VERSION ""

NS_ :

BS_:

BU_: TCU Gateway BCM PCM BECM

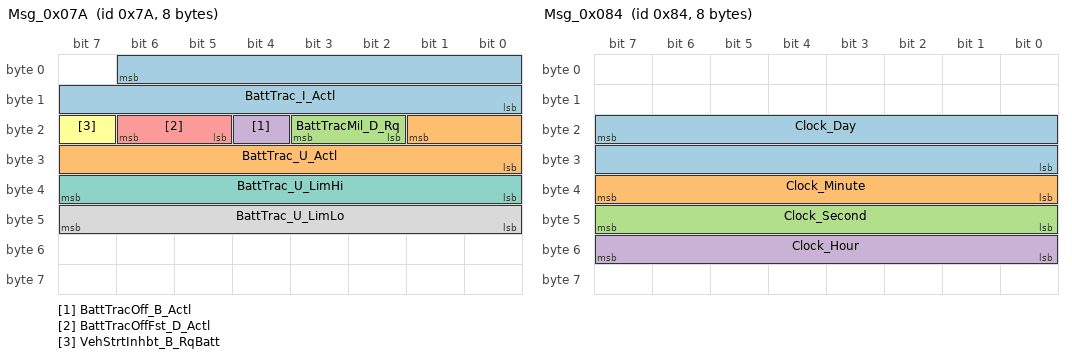
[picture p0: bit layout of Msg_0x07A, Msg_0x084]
BO_ 122 Msg_0x07A: 8 Gateway
 SG_ BattTrac_I_Actl : 6|15@0+ (0.05,-750) [-750|888.25] "A" Vector__XXX
 SG_ BattTrac_U_Actl : 17|10@0+ (0.5,0) [0|510.5] "V" Vector__XXX
 SG_ BattTracMil_D_Rq : 19|2@0+ (1,0) [0|3] "" Vector__XXX
 SG_ BattTracOff_B_Actl : 20|1@0+ (1,0) [0|1] "" Vector__XXX
 SG_ BattTracOffFst_D_Actl : 22|2@0+ (1,0) [0|3] "" Vector__XXX
 SG_ VehStrtInhbt_B_RqBatt : 23|1@0+ (1,0) [0|1] "" Vector__XXX
 SG_ BattTrac_U_LimHi : 39|8@0+ (2,0) [0|510] "V" Vector__XXX
 SG_ BattTrac_U_LimLo : 47|8@0+ (2,0) [0|510] "V" Vector__XXX

BO_ 132 Msg_0x084: 8 Gateway
 SG_ Clock_Day : 23|16@0+ (1,0) [0|65535] "" Vector__XXX
 SG_ Clock_Minute : 39|8@0+ (1,0) [0|59] "min" Vector__XXX
 SG_ Clock_Second : 47|8@0+ (1,0) [0|59] "s" Vector__XXX
 SG_ Clock_Hour : 55|8@0+ (1,0) [0|23] "h" Vector__XXX

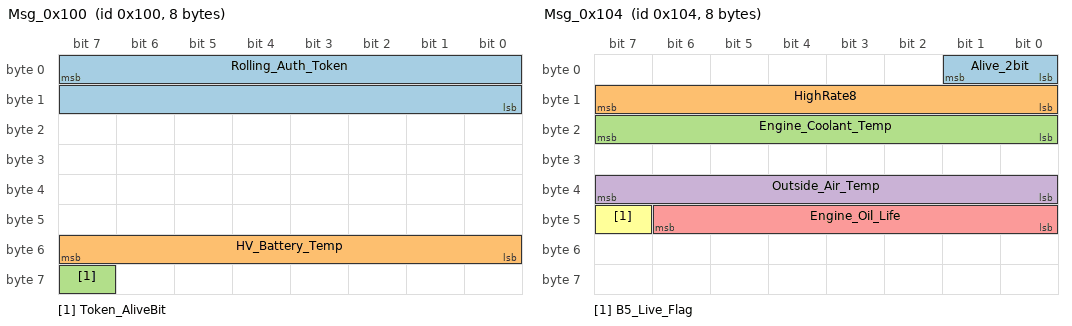
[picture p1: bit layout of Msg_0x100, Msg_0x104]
BO_ 256 Msg_0x100: 8 BCM
 SG_ Rolling_Auth_Token : 7|16@0+ (1,0) [0|65535] "" Vector__XXX
 SG_ HV_Battery_Temp : 55|8@0+ (0.5,-50) [-40|80] "degC" Vector__XXX
 SG_ Token_AliveBit : 63|1@0+ (1,0) [0|1] "" Vector__XXX

BO_ 257 Msg_0x101: 8 Gateway
 SG_ Brake_Pressed : 32|1@0+ (1,0) [0|1] "" Vector__XXX
 SG_ Gear_Selector : 29|2@0+ (1,0) [0|3] "" Vector__XXX

BO_ 259 Msg_0x103: 8 Gateway
 SG_ Accelerator_Demand : 7|16@0+ (0.1887,-24188) [0|100] "%" Vector__XXX
 SG_ Engine_RPM_Raw : 23|16@0+ (2,-114688) [0|8000] "rpm" Vector__XXX

BO_ 260 Msg_0x104: 8 Gateway
 SG_ Alive_2bit : 1|2@0+ (1,0) [0|3] "" Vector__XXX
 SG_ HighRate8 : 15|8@0+ (1,0) [0|255] "" Vector__XXX
 SG_ Engine_Coolant_Temp : 23|8@0+ (1.0,-60) [-40|140] "degC" Vector__XXX
 SG_ Outside_Air_Temp : 39|8@0+ (0.25,0) [0|63.5] "degC" Vector__XXX
 SG_ Engine_Oil_Life : 46|7@0+ (1,0) [0|100] "%" Vector__XXX
 SG_ B5_Live_Flag : 47|1@0+ (1,0) [0|1] "" Vector__XXX

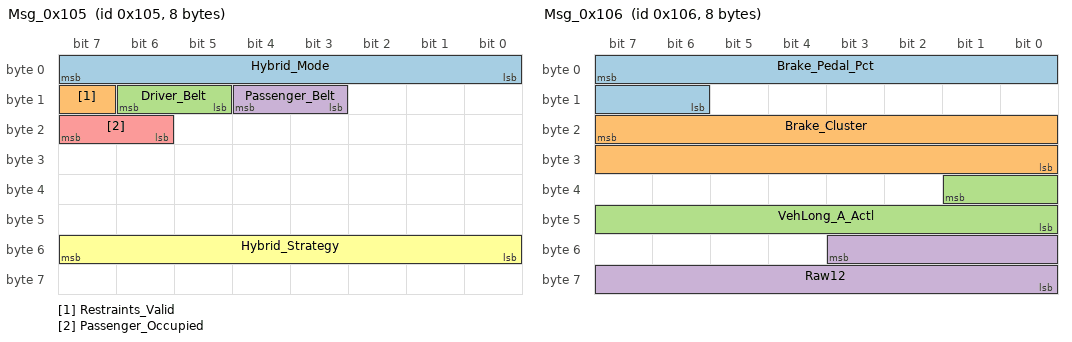
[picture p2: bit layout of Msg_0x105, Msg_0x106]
BO_ 261 Msg_0x105: 8 Gateway
 SG_ Hybrid_Mode : 7|8@0+ (1,0) [0|255] "" Vector__XXX
 SG_ Restraints_Valid : 15|1@0+ (1,0) [0|1] "" Vector__XXX
 SG_ Driver_Belt : 14|2@0+ (1,0) [0|3] "" Vector__XXX
 SG_ Passenger_Belt : 12|2@0+ (1,0) [0|3] "" Vector__XXX
 SG_ Passenger_Occupied : 23|2@0+ (1,0) [0|3] "" Vector__XXX
 SG_ Hybrid_Strategy : 55|8@0+ (1,0) [0|255] "" Vector__XXX

BO_ 262 Msg_0x106: 8 Gateway
 SG_ Brake_Pedal_Pct : 7|10@0+ (0.09775,0) [0|100] "%" Vector__XXX
 SG_ Brake_Cluster : 23|16@0+ (1,0) [0|65535] "" Vector__XXX
 SG_ VehLong_A_Actl : 33|10@0+ (0.035,-17.9) [-17.9|17.85] "m/s2" Vector__XXX
 SG_ Raw12 : 51|12@0+ (1,0) [0|4095] "" Vector__XXX

BO_ 263 Msg_0x107: 8 Gateway
 SG_ Vehicle_Speed : 7|16@0+ (0.01,0) [0|260] "km/h" Vector__XXX
 SG_ Park_Latch : 23|8@0+ (1,0) [0|255] "" Vector__XXX

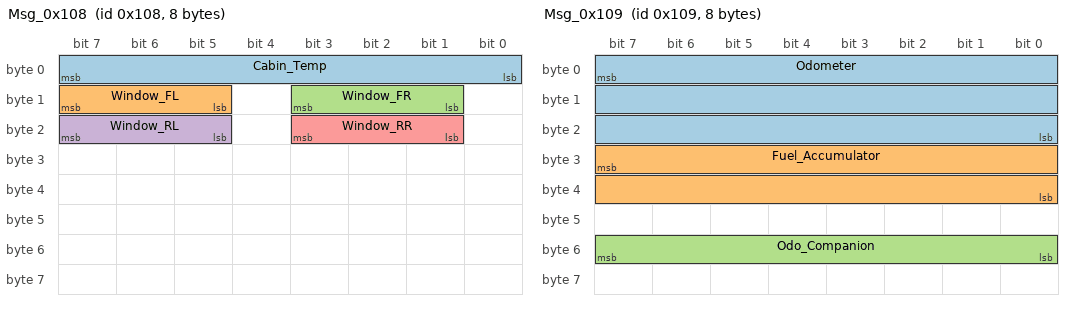
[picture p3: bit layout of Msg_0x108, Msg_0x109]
BO_ 264 Msg_0x108: 8 Gateway
 SG_ Cabin_Temp : 7|8@0+ (0.5,-57) [-40|80] "degC" Vector__XXX
 SG_ Window_FL : 15|3@0+ (25,-25) [0|100] "%" Vector__XXX
 SG_ Window_FR : 11|3@0+ (25,-25) [0|100] "%" Vector__XXX
 SG_ Window_RL : 23|3@0+ (25,-25) [0|100] "%" Vector__XXX
 SG_ Window_RR : 19|3@0+ (25,-25) [0|100] "%" Vector__XXX

BO_ 265 Msg_0x109: 8 Gateway
 SG_ Odometer : 7|24@0+ (1,0) [0|2000000] "km" Vector__XXX
 SG_ Fuel_Accumulator : 31|16@0+ (1,0) [0|65535] "" Vector__XXX
 SG_ Odo_Companion : 55|8@0+ (1,0) [0|255] "" Vector__XXX

BO_ 266 Msg_0x10A: 8 Gateway
 SG_ Transaxle_State : 23|8@0+ (1,0) [0|255] "" Vector__XXX

BO_ 268 Msg_0x10C: 8 Gateway
 SG_ Component_Temp_Raw : 7|8@0+ (1,0) [0|255] "" Vector__XXX
 SG_ Motor_Temp : 55|8@0+ (1,0) [20|120] "degC" Vector__XXX

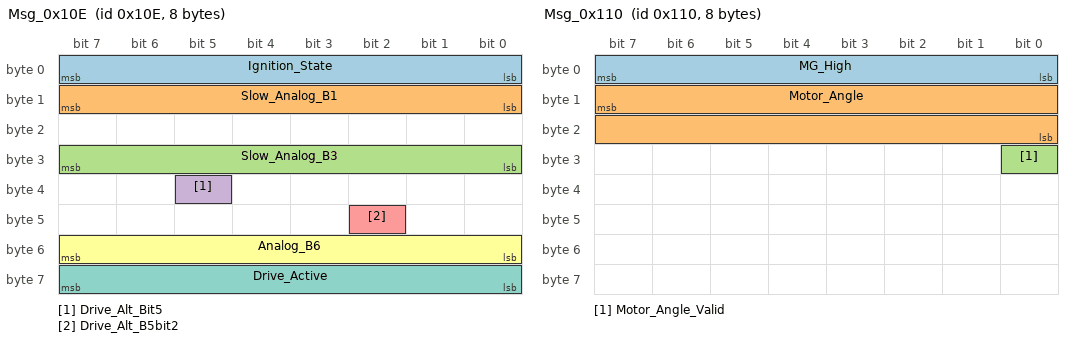
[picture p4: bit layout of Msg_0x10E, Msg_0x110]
BO_ 270 Msg_0x10E: 8 BCM
 SG_ Ignition_State : 7|8@0+ (1,0) [0|255] "" Vector__XXX
 SG_ Slow_Analog_B1 : 15|8@0+ (1,0) [0|255] "" Vector__XXX
 SG_ Slow_Analog_B3 : 31|8@0+ (1,0) [0|255] "" Vector__XXX
 SG_ Drive_Alt_Bit5 : 37|1@0+ (1,0) [0|1] "" Vector__XXX
 SG_ Drive_Alt_B5bit2 : 42|1@0+ (1,0) [0|1] "" Vector__XXX
 SG_ Analog_B6 : 55|8@0+ (1,0) [0|255] "" Vector__XXX
 SG_ Drive_Active : 63|8@0+ (1,0) [0|255] "" Vector__XXX

BO_ 271 Msg_0x10F: 8 Gateway
 SG_ HighRate_Raw16 : 7|16@0+ (1,0) [0|65535] "" Vector__XXX

BO_ 272 Msg_0x110: 8 Gateway
 SG_ MG_High : 7|8@0+ (1,0) [0|255] "" Vector__XXX
 SG_ Motor_Angle : 15|16@0+ (0.005493164,0) [0|359.995] "deg" Vector__XXX
 SG_ Motor_Angle_Valid : 24|1@0+ (1,0) [0|1] "" Vector__XXX

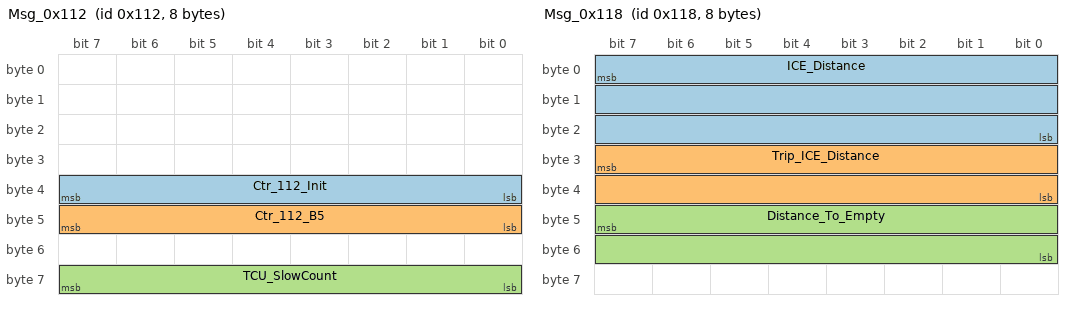
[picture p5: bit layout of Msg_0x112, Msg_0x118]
BO_ 274 Msg_0x112: 8 Vector__XXX
 SG_ Ctr_112_Init : 39|8@0+ (1,0) [0|255] "" Vector__XXX
 SG_ Ctr_112_B5 : 47|8@0+ (1,0) [0|232] "" Vector__XXX
 SG_ TCU_SlowCount : 63|8@0+ (1,0) [0|255] "" Vector__XXX

BO_ 275 Msg_0x113: 8 Gateway
 SG_ Trip_Fuel_Used : 15|8@0+ (0.1,0) [0|25.5] "L" Vector__XXX
 SG_ Trip_Distance : 39|16@0+ (0.1,0) [0|6553.5] "km" Vector__XXX

BO_ 280 Msg_0x118: 8 Gateway
 SG_ ICE_Distance : 7|24@0+ (0.1,0) [0|1677721] "km" Vector__XXX
 SG_ Trip_ICE_Distance : 31|16@0+ (0.1,0) [0|6553.5] "km" Vector__XXX
 SG_ Distance_To_Empty : 47|16@0+ (0.1,0) [0|6553.5] "km" Vector__XXX

BO_ 282 Msg_0x11A: 8 Gateway
 SG_ VIN_Multiplex_Index : 15|8@0+ (1,0) [0|255] "" Vector__XXX

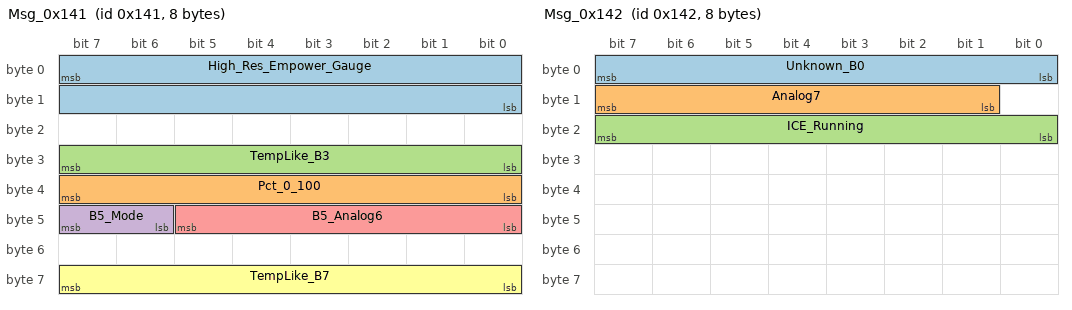
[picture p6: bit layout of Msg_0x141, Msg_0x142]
BO_ 321 Msg_0x141: 8 Gateway
 SG_ High_Res_Empower_Gauge : 7|16@0+ (1,-10000) [-10000|55535] "" Vector__XXX
 SG_ Pct_0_100 : 39|8@0+ (1,0) [0|100] "%" Vector__XXX
 SG_ TempLike_B3 : 31|8@0+ (1,0) [47|98] "" Vector__XXX
 SG_ B5_Mode : 47|2@0+ (1,0) [0|3] "" Vector__XXX
 SG_ B5_Analog6 : 45|6@0+ (1,0) [31|40] "" Vector__XXX
 SG_ TempLike_B7 : 63|8@0+ (1,0) [40|98] "" Vector__XXX

BO_ 322 Msg_0x142: 8 Gateway
 SG_ Unknown_B0 : 7|8@0+ (1,0) [0|255] "" Vector__XXX
 SG_ Analog7 : 15|7@0+ (1,0) [0|127] "" Vector__XXX
 SG_ ICE_Running : 23|8@0+ (1,0) [0|255] "" Vector__XXX

BO_ 326 Msg_0x146: 8 TCU
 SG_ Tcu_Command : 7|8@0+ (1,0) [0|255] "" Vector__XXX
 SG_ Tcu_Seq : 31|8@0+ (1,0) [0|255] "" Vector__XXX

BO_ 327 Msg_0x147: 8 Gateway
 SG_ Remote_Start_Timer : 15|16@0+ (1,0) [0|900] "s" Vector__XXX
 SG_ Lamp_Mode : 47|3@0+ (1,0) [0|7] "" Vector__XXX

BO_ 339 Msg_0x153: 8 Gateway
 SG_ Trip_Avg_Mpg : 39|16@0+ (0.1,0) [0|400] "mpg" Vector__XXX

BO_ 350 Msg_0x15E: 8 Gateway
 SG_ Mux_Index M : 7|8@0+ (1,0) [0|255] "" Vector__XXX
 SG_ Clock_Minute_Mux m1 : 23|8@0+ (1,0) [0|59] "min" Vector__XXX
 SG_ Clock_Second_Mux m1 : 31|8@0+ (1,0) [0|59] "s" Vector__XXX
 SG_ Gps_Lat_Raw m22 : 15|16@0+ (0.000256034,43.6591) [40|60] "deg" Vector__XXX
 SG_ Gps_Lat_Fine m22 : 31|8@0+ (1e-6,-0.000128) [-0.000128|0.000127] "deg" Vector__XXX
 SG_ Gps_Lon_Raw m22 : 47|16@0+ (0.000016,5.0) [5|6.05] "deg" Vector__XXX
 SG_ Gnss_Distance_Raw m48 : 15|8@0+ (1,0) [0|255] "" Vector__XXX
 SG_ Gnss_PDOP m48 : 23|8@0+ (0.1,0) [0|25.4] "" Vector__XXX
 SG_ Gnss_HDOP m48 : 31|8@0+ (0.1,0) [0|25.4] "" Vector__XXX
 SG_ Gnss_VDOP m48 : 39|8@0+ (0.1,0) [0|25.4] "" Vector__XXX

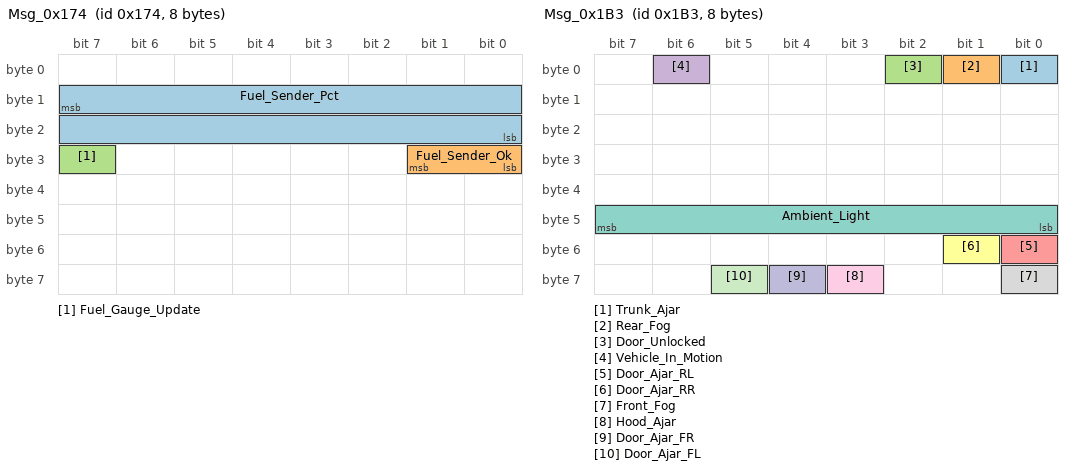
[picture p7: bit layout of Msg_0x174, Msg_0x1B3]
BO_ 372 Msg_0x174: 8 Gateway
 SG_ Fuel_Sender_Pct : 15|16@0+ (0.1,0) [0|100] "%" Vector__XXX
 SG_ Fuel_Sender_Ok : 25|2@0+ (1,0) [0|3] "" Vector__XXX
 SG_ Fuel_Gauge_Update : 31|1@0+ (1,0) [0|1] "" Vector__XXX

BO_ 373 Msg_0x175: 8 Gateway
 SG_ Steering_Angle : 31|16@0+ (0.1,-819.2) [-819.2|819.1] "deg" Vector__XXX

BO_ 435 Msg_0x1B3: 8 BCM
 SG_ Trunk_Ajar : 0|1@0+ (1,0) [0|1] "" Vector__XXX
 SG_ Rear_Fog : 1|1@0+ (1,0) [0|1] "" Vector__XXX
 SG_ Door_Unlocked : 2|1@0+ (1,0) [0|1] "" Vector__XXX
 SG_ Vehicle_In_Motion : 6|1@0+ (1,0) [0|1] "" Vector__XXX
 SG_ Door_Ajar_RL : 48|1@0+ (1,0) [0|1] "" Vector__XXX
 SG_ Door_Ajar_RR : 49|1@0+ (1,0) [0|1] "" Vector__XXX
 SG_ Ambient_Light : 47|8@0+ (1,0) [0|255] "" Vector__XXX
 SG_ Front_Fog : 56|1@0+ (1,0) [0|1] "" Vector__XXX
 SG_ Hood_Ajar : 59|1@0+ (1,0) [0|1] "" Vector__XXX
 SG_ Door_Ajar_FR : 60|1@0+ (1,0) [0|1] "" Vector__XXX
 SG_ Door_Ajar_FL : 61|1@0+ (1,0) [0|1] "" Vector__XXX

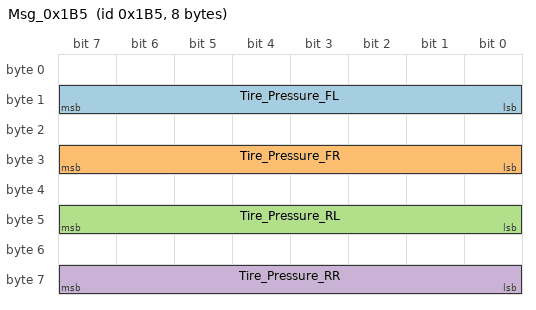
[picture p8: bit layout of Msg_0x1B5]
BO_ 437 Msg_0x1B5: 8 BCM
 SG_ Tire_Pressure_FL : 15|8@0+ (0.01,0) [0|2.55] "bar" Vector__XXX
 SG_ Tire_Pressure_FR : 31|8@0+ (0.01,0) [0|2.55] "bar" Vector__XXX
 SG_ Tire_Pressure_RL : 47|8@0+ (0.01,0) [0|2.55] "bar" Vector__XXX
 SG_ Tire_Pressure_RR : 63|8@0+ (0.01,0) [0|2.55] "bar" Vector__XXX

BO_ 554 Msg_0x22A: 8 TCU
 SG_ TcuCmd_Active : 63|8@0+ (1,0) [0|1] "" Vector__XXX

BO_ 1424 Msg_0x590: 8 TCU
 SG_ NM_Source : 7|8@0+ (1,0) [0|255] "" Vector__XXX

BO_ 1438 Msg_0x59E: 8 Gateway
 SG_ GWM_NM : 7|8@0+ (1,0) [0|255] "" Vector__XXX

CM_ BO_ 350 "Mux 0x16/0x76/0x86 = GPS (B1:B2 lat, B5:B6 lon). Mux 0x01 = MM:SS clock. Mux 0x30 = GNSS DOP precision (B2 PDOP, B3 HDOP, B4 VDOP, scale 0.1, 00/FF invalid).";
CM_ SG_ 268 Motor_Temp "NOT motor temp. Live 64-77 / off 0. Retracted — see docs/signals.md.";
CM_ SG_ 321 High_Res_Empower_Gauge "16-bit analog cluster gauge. 10000 = 0 kW. < 10000 is regen, > 10000 is power. Was previously misidentified as Coarse HV Current (B0) + Intake MAP (B1:B2) due to byte misalignment.";
CM_ SG_ 272 Motor_Angle "B1:B2 * 360/65536 deg. B3 bit7 resolver-valid. FF FF FF asleep.";
CM_ SG_ 372 Fuel_Sender_Pct "B1:B2 BE * 0.1 %. NOT the tank level: 1000 sentinel most of the time, short 70-99 % bursts. Use 0x118 DTE. raw 0 and 1000 are invalid.";
CM_ SG_ 372 Fuel_Sender_Ok "B3 bits 0-1. Always 3 in every capture. Likely sender OK / data valid.";
CM_ SG_ 372 Fuel_Gauge_Update "B3 bit 7. NOT the low-fuel lamp. 1-5 s strobe at <7 km/h when filtered % commits. Real lamp unmapped — see docs/signals.md.";
CM_ SG_ 322 ICE_Running "0x64 = EV, 0x68 = ICE running.";
CM_ SG_ 322 Unknown_B0 "Not outside temperature (retracted 2026-11-07): 0x4E whenever parked, swings 0x44-0x57 while driving.";
CM_ SG_ 260 Outside_Air_Temp "CANDIDATE 2026-11-07: within ~1 degC of OBD Outside Temperature in 4 paired drives (10-23 degC seen). Below 0 degC unknown.";
CM_ SG_ 261 Hybrid_Mode "0xE0 parked, 0xE8 city/EV-heavy, 0xF8 highway.";
CM_ SG_ 339 Trip_Avg_Mpg "Native 0.1 US mpg/LSB. Metric conversion: L/100 km = 235.215 / mpg.";
CM_ SG_ 274 Ctr_112_Init "B4 00 = counter block not initialised, 03 = initialised (B4:B5 >= 768). Latches 2-3 min into a drive. NOT motion. Formerly TCU_Motion.";
CM_ SG_ 435 Ambient_Light "BCM twilight level: 00 dark, 01 dawn/dusk, 05 daylight. Formerly mislabelled TCU_Presence. Reads 00 in the wake/sleep boundary frame (B1=00) - ignore it there.";
CM_ SG_ 327 Lamp_Mode "Exterior lamp mode, B5 bits 7:5. DRLs switch off on the indicating side (3/4). Parking (2) is tentative.";
CM_ SG_ 256 HV_Battery_Temp "Traction battery temperature. Was Token_SlowCount; it falls while parked, so not a counter.";
CM_ SG_ 264 Cabin_Temp "Candidate. Was Hybrid_SOC (retracted, r=0.26 vs real SOC).";
CM_ SG_ 264 Window_FL "Driver window, B1 high nibble bits 3:1: 1=closed .. 5=fully open.";
CM_ SG_ 264 Window_FR "Passenger window, B1 low nibble bits 3:1.";
CM_ SG_ 264 Window_RL "Rear-left window, B2 high nibble bits 3:1.";
CM_ SG_ 264 Window_RR "Rear-right window, B2 low nibble bits 3:1.";
CM_ SG_ 257 Gear_Selector "Rotary gear dial, B3 bits 5:4. A P-to-D turn passes R and N within ~0.4 s.";
CM_ SG_ 261 Driver_Belt "B1 bits 6:5. Not reported while Restraints_Valid (B1 bit 7) is 0 after ignition on.";
CM_ SG_ 261 Passenger_Belt "B1 bits 4:3.";
CM_ SG_ 261 Passenger_Occupied "B2 bits 7:6. Seat weight sensor; clears ~20 s after the seat empties.";
VAL_ 257 Gear_Selector 0 "P" 1 "R" 2 "N" 3 "D" ;
VAL_ 261 Driver_Belt 1 "Buckled" 2 "Unbuckled" 3 "Init" ;
VAL_ 261 Passenger_Belt 1 "Buckled" 2 "Unbuckled" 3 "Init" ;
VAL_ 261 Passenger_Occupied 1 "Occupied" 2 "Empty" 3 "Init" ;
VAL_ 327 Lamp_Mode 0 "Off" 1 "LowBeam" 2 "Parking" 3 "DRL_RightOff" 4 "DRL_LeftOff" 5 "DRL" ;
CM_ SG_ 260 Engine_Oil_Life "Oil life remaining %, B5 bits 6:0 (PCM EngOilLife_Pc_Actl).";
